# puf_reva register map
Registers are read-write, no defined reset value unless marked. A register's access mark holds for its fields unless they carry their own. Offsets are from the block's base; lines under a group give offsets from that group; [hi:lo] are bit positions; {n}, {i} and the like mark numbered series; 'fields as' and 'values as' point back to an identical list; <NAME> marks a mode.

## Memory map
0x40007000 PUF size 0x400 — PUF Registers

## PUF — PUF Registers
Base 0x40007000
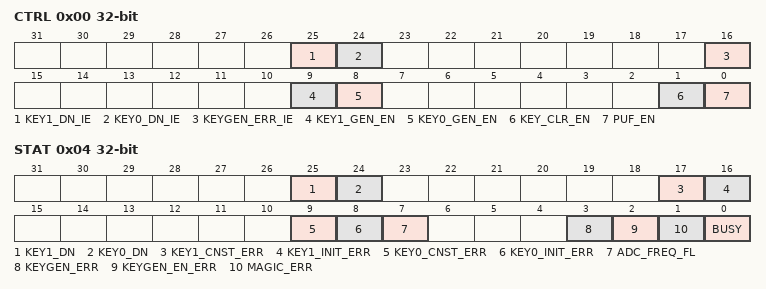
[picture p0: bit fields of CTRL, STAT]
0x00 CTRL — PUF Control Register.
  [25] KEY1_DN_IE — Key1 Done Interrupt Enable
  [24] KEY0_DN_IE — Key0 Done Interrupt Enable.
  [16] KEYGEN_ERR_IE — Key Generation Error Interrupt Enable.
  [9] KEY1_GEN_EN — PUF Key1 Generation Enable.
  [8] KEY0_GEN_EN — PUF Key0 Generation Enable.
  [1] KEY_CLR_EN — Key Clear Enable or PUFSEC Disable
  [0] PUF_EN — PUF Controller Enable.
0x04 STAT — PUF Status Register.
  [25] KEY1_DN — Key1 Done.
  [24] KEY0_DN — Key0 Done.
  [17] KEY1_CNST_ERR — PUF Key1 Constant Key Mismatch Error
  [16] KEY1_INIT_ERR — PUF Key1 Initialization Error.
  [9] KEY0_CNST_ERR — PUF Key0 Constant Key Mismatch Error
  [8] KEY0_INIT_ERR — PUF Key0 Initialization Error.
  [7] ADC_FREQ_FL — ADC Frequency Flag
  [3] KEYGEN_ERR — PUF Magic Word Error.
  [2] KEYGEN_EN_ERR — PUF Magic Word Error.
  [1] MAGIC_ERR — PUF Magic Word Error.
  [0] BUSY — PUF Controller Busy.
